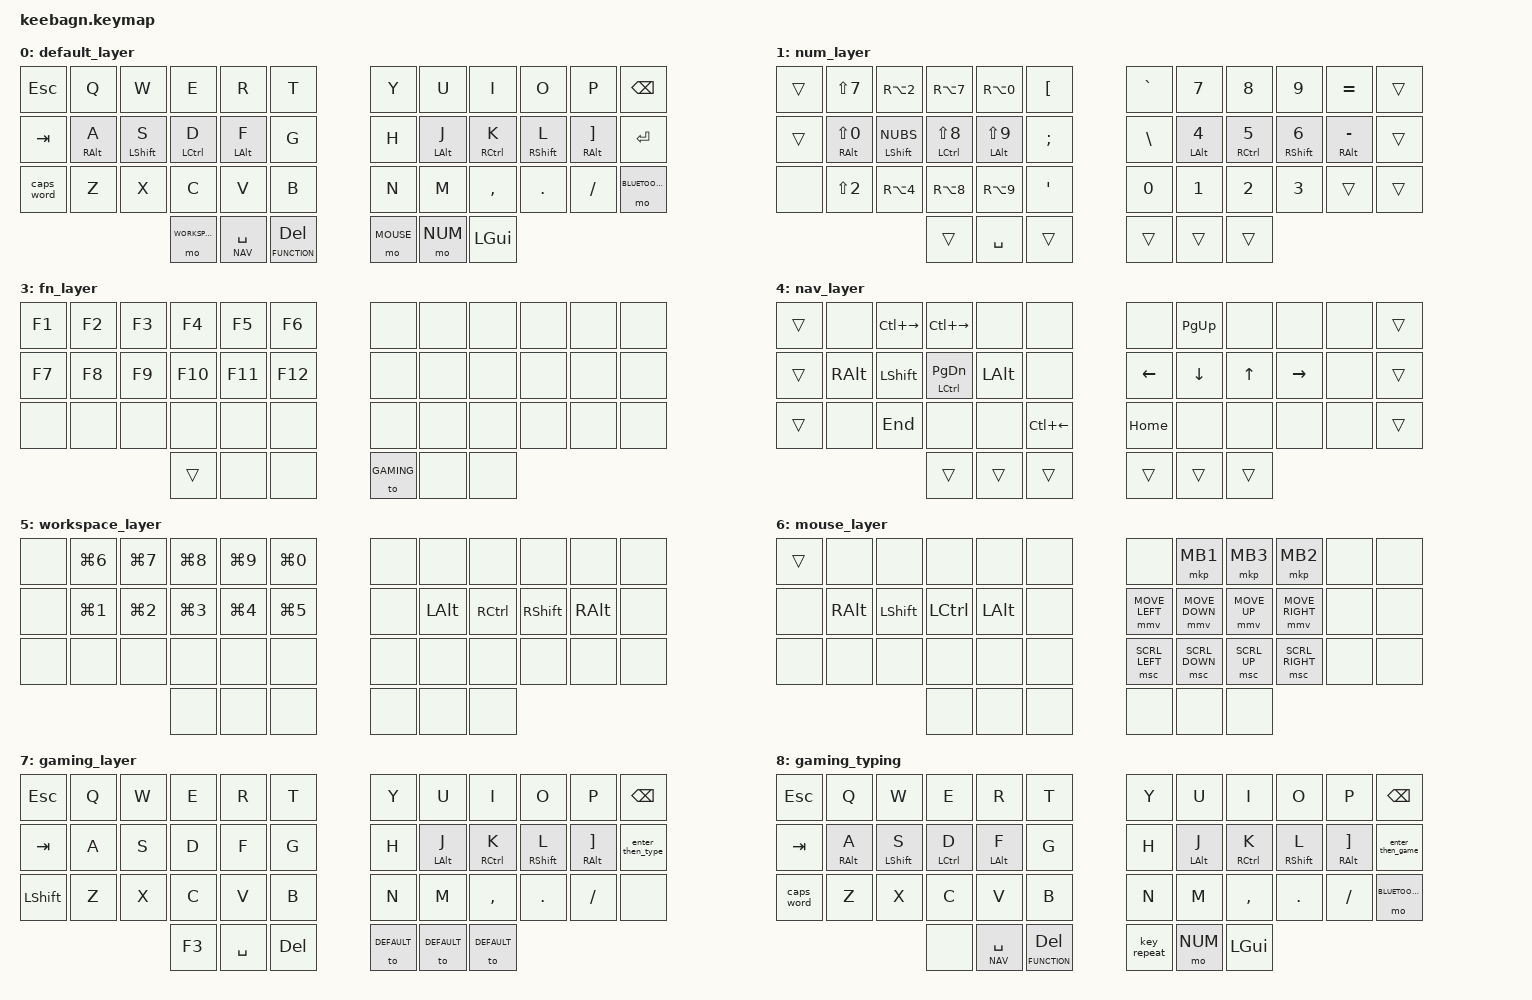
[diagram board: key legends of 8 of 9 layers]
/*
 * Copyright (c) 2020 The ZMK Contributors
 *
 * SPDX-License-Identifier: MIT
 */
#include <behaviors.dtsi>
#include <dt-bindings/zmk/keys.h>
#include <dt-bindings/zmk/bt.h>
#include <dt-bindings/zmk/outputs.h>
#include <dt-bindings/zmk/pointing.h>

#define DEFAULT 0
#define NUM 1
#define BLUETOOTH 2
#define FUNCTION 3
#define NAV 4
#define WORKSPACE 5
#define MOUSE 6
#define GAMING 7
#define GAMING_TYPING 8

&kscan0 {
    debounce-press-ms = <4>;
    debounce-release-ms = <4>;
};

&caps_word {
    continue-list = <SLASH DELETE BACKSPACE LSHFT RSHFT>;
};

/ {
    behaviors {
        hm: homerow_mods {
            compatible = "zmk,behavior-hold-tap";
            label = "HOMEROW_MODS";
            #binding-cells = <2>;
            tapping-term-ms = <150>;
            quick-tap-ms = <0>;
            flavor = "tap-preferred";
            bindings = <&kp>, <&kp>;
        };

    };
    macros {
        enter_then_type: enter_then_type {
            compatible = "zmk,behavior-macro";
            #binding-cells = <0>;
            bindings
                = <&macro_tap &kp ENTER>
                , <&macro_tap &to GAMING_TYPING>
                ;
        };
        enter_then_game: enter_then_game {
            compatible = "zmk,behavior-macro";
            #binding-cells = <0>;
            bindings
                = <&macro_tap &kp ENTER>
                , <&macro_tap &to GAMING>
                ;
        };
    };

    keymap {
        compatible = "zmk,keymap";

        default_layer {
            bindings = <
&kp ESC      &kp Q      &kp W       &kp E       &kp R      &kp T           &kp Y &kp U      &kp I        &kp O        &kp P          &kp BSPC
&kp TAB      &hm RALT A &hm LSHFT S &hm LCTRL D &hm LALT F &kp G           &kp H &hm LALT J &hm RCTRL K  &hm RSHFT L  &hm RALT RBKT  &kp ENTER
&caps_word   &kp Z      &kp X       &kp C       &kp V      &kp B           &kp N &kp M      &kp COMMA    &kp PERIOD   &kp SLASH      &mo BLUETOOTH
                &mo WORKSPACE  &lt NAV SPACE &lt FUNCTION DELETE           &mo MOUSE  &mo NUM  &kp LEFT_GUI
            >;
        };

        num_layer {
            bindings = <
&trans  &kp LS(N7)       &kp RA(N2)         &kp RA(N7)        &kp RA(N0)       &kp LBKT             &kp GRAVE  &kp N7        &kp N8         &kp N9         &kp EQUAL        &trans
&trans  &hm RALT LS(N0)  &hm LSHFT NUBS     &hm LCTRL LS(N8)  &hm LALT LS(N9)  &kp SEMI             &kp BSLH   &hm LALT N4   &hm RCTRL N5   &hm RSHFT N6   &hm RALT MINUS   &trans
&none   &kp LS(N2)       &kp RA(N4)         &kp RA(N8)        &kp RA(N9)       &kp SQT              &kp N0     &kp N1        &kp N2         &kp N3         &trans           &trans
                                                            &trans  &kp SPACE  &trans               &trans    &trans     &trans
            >;
        };

        bt_layer {
            bindings = <
&none  &none         &none         &none         &none         &none                   &none    &kp C_BRI_UP  &kp C_VOL_UP    &none    &none  &none
&none  &bt BT_SEL 0  &bt BT_SEL 1  &bt BT_SEL 2  &bt BT_SEL 3  &bt BT_SEL 4            &none    &kp C_BRI_DN  &kp C_VOL_DN    &none    &none  &none
&none  &none         &out OUT_USB  &out OUT_BLE  &bt BT_CLR    &none                   &none    &none         &kp C_MUTE      &none    &none
                                    &none         &none        &none                   &none    &none    &none
            >;
        };

        fn_layer {
            bindings = <
&kp F1  &kp F2    &kp F3     &kp F4     &kp F5    &kp F6          &none    &none  &none    &none    &none  &none
&kp F7  &kp F8    &kp F9     &kp F10    &kp F11   &kp F12         &none    &none  &none    &none    &none  &none
&none   &none     &none      &none      &none     &none           &none    &none  &none    &none    &none  &none
                                 &trans    &none  &none           &to GAMING    &none    &none
            >;
        };

        nav_layer {
            bindings = <
&trans  &none     &kp LC(RIGHT)  &kp LC(RIGHT)    &none     &none              &none     &kp PG_UP  &none      &none      &none     &trans
&trans  &kp RALT  &kp LSHFT      &hm LCTRL PG_DN  &kp LALT  &none              &kp LEFT  &kp DOWN   &kp UP     &kp RIGHT  &none     &trans
&trans  &none     &kp END        &none            &none     &kp LC(LEFT)       &kp HOME  &none      &none      &none      &none     &trans
                                          &trans    &trans  &trans             &trans    &trans     &trans
            >;
        };

        workspace_layer {
            bindings = <
&none &kp LG(N6) &kp LG(N7) &kp LG(N8) &kp LG(N9) &kp LG(N0)       &none &none     &none     &none      &none    &none
&none &kp LG(N1) &kp LG(N2) &kp LG(N3) &kp LG(N4) &kp LG(N5)       &none &kp LALT  &kp RCTRL &kp RSHFT  &kp RALT &none
&none &none      &none      &none      &none      &none            &none &none     &none     &none      &none    &none
                                      &none &none &none            &none &none &none
            >;
        };
        
        mouse_layer {
            bindings = <
&trans  &none     &none      &none      &none     &none        &none           &mkp MB1        &mkp MB3      &mkp MB2         &none  &none
&none   &kp RALT  &kp LSHFT  &kp LCTRL  &kp LALT  &none        &mmv MOVE_LEFT  &mmv MOVE_DOWN  &mmv MOVE_UP  &mmv MOVE_RIGHT  &none  &none
&none   &none     &none      &none      &none     &none        &msc SCRL_LEFT  &msc SCRL_DOWN  &msc SCRL_UP  &msc SCRL_RIGHT  &none  &none
                                    &none  &none  &none        &none  &none  &none
            >;
        };

        gaming_layer {
            bindings = <
&kp ESC    &kp Q      &kp W    &kp E   &kp R    &kp T            &kp Y     &kp U       &kp I        &kp O        &kp P          &kp BSPC
&kp TAB    &kp A      &kp S    &kp D   &kp F    &kp G            &kp H     &hm LALT J  &hm RCTRL K  &hm RSHFT L  &hm RALT RBKT  &enter_then_type
&kp LSHFT  &kp Z      &kp X    &kp C   &kp V    &kp B            &kp N     &kp M       &kp COMMA    &kp PERIOD   &kp SLASH      &none
                            &kp F3   &kp SPACE  &kp DELETE       &to DEFAULT   &to DEFAULT &to DEFAULT
            >;
        };
        gaming_typing {
            bindings = <
&kp ESC      &kp Q      &kp W       &kp E       &kp R      &kp T           &kp Y &kp U      &kp I        &kp O        &kp P          &kp BSPC
&kp TAB      &hm RALT A &hm LSHFT S &hm LCTRL D &hm LALT F &kp G           &kp H &hm LALT J &hm RCTRL K  &hm RSHFT L  &hm RALT RBKT  &enter_then_game
&caps_word   &kp Z      &kp X       &kp C       &kp V      &kp B           &kp N &kp M      &kp COMMA    &kp PERIOD   &kp SLASH      &mo BLUETOOTH
                    &none      &lt NAV SPACE &lt FUNCTION DELETE           &key_repeat  &mo NUM  &kp LGUI
            >;
        };
    };
};
